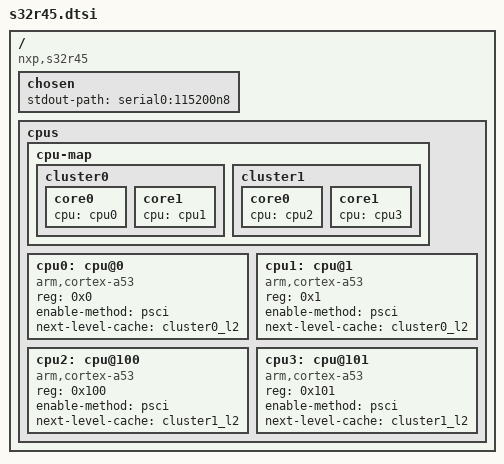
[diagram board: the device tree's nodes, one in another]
// SPDX-License-Identifier: GPL-2.0-or-later OR MIT
/*
 * Copyright 2017-2022 NXP
 */

/dts-v1/;
#include "s32cc.dtsi"

/ {
	compatible = "nxp,s32r45";

	chosen {
		stdout-path = "serial0:115200n8";
	};

	cpus {
		cpu-map {
			cluster0 {
				core0 {
					cpu = <&cpu0>;
				};

				core1 {
					cpu = <&cpu1>;
				};
			};

			cluster1 {
				core0 {
					cpu = <&cpu2>;
				};

				core1 {
					cpu = <&cpu3>;
				};
			};
		};

		cpu0: cpu@0 {
			device_type = "cpu";
			compatible = "arm,cortex-a53";
			reg = <0x0>;
			enable-method = "psci";
			next-level-cache = <&cluster0_l2>;
		};

		cpu1: cpu@1 {
			device_type = "cpu";
			compatible = "arm,cortex-a53";
			reg = <0x1>;
			enable-method = "psci";
			next-level-cache = <&cluster0_l2>;
		};

		cpu2: cpu@100 {
			device_type = "cpu";
			compatible = "arm,cortex-a53";
			reg = <0x100>;
			enable-method = "psci";
			next-level-cache = <&cluster1_l2>;
		};

		cpu3: cpu@101 {
			device_type = "cpu";
			compatible = "arm,cortex-a53";
			reg = <0x101>;
			enable-method = "psci";
			next-level-cache = <&cluster1_l2>;
		};
	};
};
